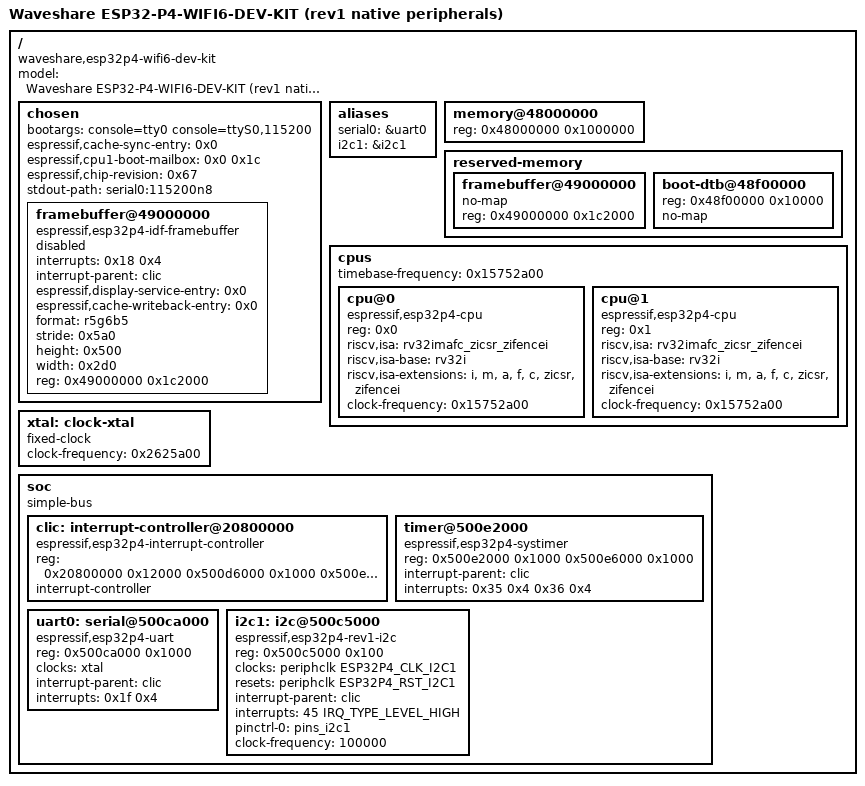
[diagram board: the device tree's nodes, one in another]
// SPDX-License-Identifier: (GPL-2.0-only OR BSD-2-Clause)
/dts-v1/;

#include <dt-bindings/clock/esp32p4-peripheral-clock.h>
#include <dt-bindings/interrupt-controller/irq.h>

/ {
	/* Opt-in for this PCB and rev1 silicon only; not a recovery DTB. */
	model = "Waveshare ESP32-P4-WIFI6-DEV-KIT (rev1 native peripherals)";
	compatible = "waveshare,esp32p4-wifi6-dev-kit", "espressif,esp32p4-generic",
		     "espressif,esp32p4";
	#address-cells = <0x1>;
	#size-cells = <0x1>;

	chosen {
		ranges;
		bootargs = "console=tty0 console=ttyS0,115200";
		#size-cells = <0x1>;
		#address-cells = <0x1>;
		espressif,cache-sync-entry = <0x0>;
		espressif,cpu1-boot-mailbox = <0x0 0x1c>;
		espressif,chip-revision = <0x67>;
		stdout-path = "serial0:115200n8";

		framebuffer@49000000 {
			interrupts = <0x18 0x4>;
			interrupt-parent = <&clic>;
			espressif,display-service-entry = <0x0>;
			espressif,cache-writeback-entry = <0x0>;
			status = "disabled";
			format = "r5g6b5";
			stride = <0x5a0>;
			height = <0x500>;
			width = <0x2d0>;
			reg = <0x49000000 0x1c2000>;
			compatible = "espressif,esp32p4-idf-framebuffer";
		};
	};

	aliases {
		serial0 = &uart0;
		i2c1 = &i2c1;
	};

	memory@48000000 {
		device_type = "memory";
		reg = <0x48000000 0x1000000>;
	};

	reserved-memory {
		#address-cells = <0x1>;
		#size-cells = <0x1>;
		ranges;

		framebuffer@49000000 {
			no-map;
			reg = <0x49000000 0x1c2000>;
		};

		boot-dtb@48f00000 {
			reg = <0x48f00000 0x10000>;
			no-map;
		};
	};

	cpus {
		#address-cells = <0x1>;
		#size-cells = <0x0>;
		timebase-frequency = <0x15752a00>;

		cpu@0 {
			device_type = "cpu";
			compatible = "espressif,esp32p4-cpu", "riscv";
			reg = <0x0>;
			status = "okay";
			riscv,isa = "rv32imafc_zicsr_zifencei";
			riscv,isa-base = "rv32i";
			riscv,isa-extensions = "i", "m", "a", "f", "c", "zicsr", "zifencei";
			clock-frequency = <0x15752a00>;
		};

		cpu@1 {
			device_type = "cpu";
			compatible = "espressif,esp32p4-cpu", "riscv";
			reg = <0x1>;
			status = "okay";
			riscv,isa = "rv32imafc_zicsr_zifencei";
			riscv,isa-base = "rv32i";
			riscv,isa-extensions = "i", "m", "a", "f", "c", "zicsr", "zifencei";
			clock-frequency = <0x15752a00>;
		};
	};

	xtal: clock-xtal {
		compatible = "fixed-clock";
		#clock-cells = <0x0>;
		clock-frequency = <0x2625a00>;
	};

	soc {
		compatible = "simple-bus";
		#address-cells = <0x1>;
		#size-cells = <0x1>;
		ranges;

		clic: interrupt-controller@20800000 {
			compatible = "espressif,esp32p4-interrupt-controller";
			reg = <0x20800000 0x12000 0x500d6000 0x1000 0x500e5000 0x1000>;
			interrupt-controller;
			#interrupt-cells = <0x2>;
			#address-cells = <0x0>;
		};

		timer@500e2000 {
			compatible = "espressif,esp32p4-systimer";
			reg = <0x500e2000 0x1000 0x500e6000 0x1000>;
			interrupt-parent = <&clic>;
			interrupts = <0x35 0x4 0x36 0x4>;
		};

		uart0: serial@500ca000 {
			compatible = "espressif,esp32p4-uart";
			reg = <0x500ca000 0x1000>;
			clocks = <&xtal>;
			interrupt-parent = <&clic>;
			interrupts = <0x1f 0x4>;
			status = "okay";
		};

		/* Board SDA/SCL shared by codec, DSI/CSI and P6 header.
		 * Do not assume any external panel/camera is installed. */
		i2c1: i2c@500c5000 {
			compatible = "espressif,esp32p4-rev1-i2c";
			reg = <0x500c5000 0x100>;
			clocks = <&periphclk ESP32P4_CLK_I2C1>;
			resets = <&periphclk ESP32P4_RST_I2C1>;
			interrupt-parent = <&clic>;
			interrupts = <45 IRQ_TYPE_LEVEL_HIGH>;
			pinctrl-0 = <&pins_i2c1>;
			pinctrl-names = "default";
			clock-frequency = <100000>;
			#address-cells = <1>;
			#size-cells = <0>;
		};

	};
};

#include "esp32p4-waveshare-peripheral-pins.dtsi"

#include "esp32p4-waveshare-gpspi.dtsi"
#include "esp32p4-waveshare-uart.dtsi"
